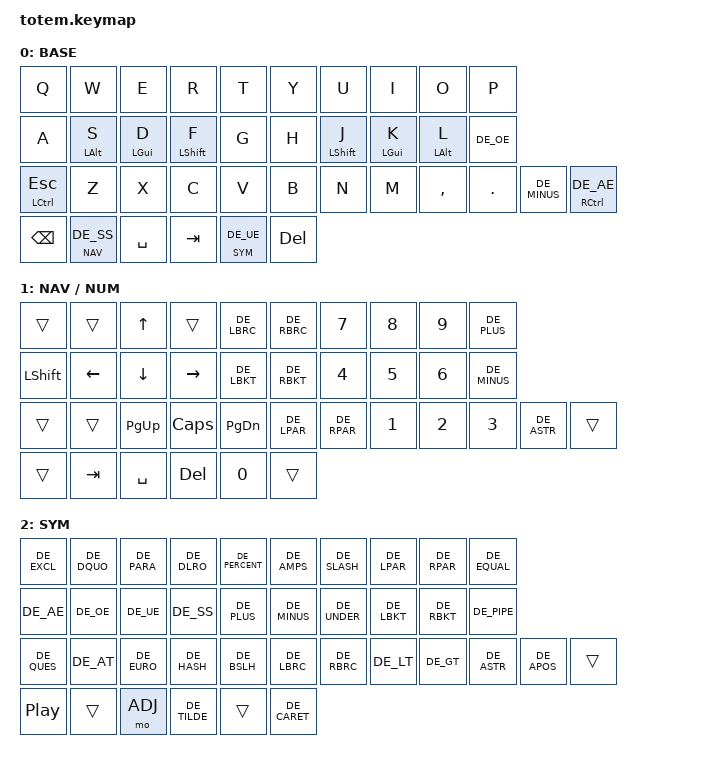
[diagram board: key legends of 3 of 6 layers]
/*
 * Totem ZMK Keymap - German macOS Optimization
 * Active working keymap for the Totem dongle setup.
 *
 * The visual layer diagrams are intentionally kept close to
 * `config/totem.keymap_original` so the layout stays easy to tune by hand.
 *
 *                                                       ▀▀▀▀▀     ▀▀▀▀▀          ▀▀█▀▀
 *                                                       ▄▀▀▀▄  ▄  ▄▀▀▀▄  ▄  ▄▀▀▀▄  █  ▄▀▀▀▄
 *                                                       █   █  █  █   █  █  █   █  █  █   █
 *                                                        ▀▀▀   █   ▀▀▀   █   ▀▀▀   ▀   ▀▀▀
 *                                                              █      ▄▄▄█▄▄▄    █   █
 *                                                              ▀      █  █  █     █▄█
 *                                                            ▀▀▀▀▀    █  █  █      ▀
 *                                                                     ▀  ▀  ▀
 */

#include <behaviors.dtsi>
#include <dt-bindings/zmk/bt.h>
#include <dt-bindings/zmk/keys.h>
#include <dt-bindings/zmk/outputs.h>

// ==================================================================================
// DEUTSCHE SONDERZEICHEN DEFINITIONEN (GERMAN CHARACTER MAPPINGS)
// ==================================================================================

// UMLAUTE & ESS-ZETT (Umlauts & Sharp S)
#define DE_UE      LBKT          // Ü
#define DE_OE      SEMI          // Ö
#define DE_AE      SQT           // Ä
#define DE_SS      MINUS         // ß

// KLAMMERN (Brackets) - German macOS optimized for Layer 2
#define DE_LBRC    LA(N8)        // { (Option+8)
#define DE_RBRC    LA(N9)        // } (Option+9)
#define DE_LBKT    LA(N5)        // [ (Option+5)
#define DE_RBKT    LA(N6)        // ] (Option+6)
#define DE_LPAR    LS(N8)        // (
#define DE_RPAR    LS(N9)        // )

// MATHEMATISCHE ZEICHEN (Math & Operators)
#define DE_PLUS    RBKT          // +
#define DE_MINUS   FSLH          // -
#define DE_EQUAL   LS(N0)        // =
#define DE_ASTR    LS(RBKT)      // *
#define DE_SLASH   LS(N7)        // /
#define DE_BSLH    LA(LS(N7))    // \ (Option+Shift+7)
#define DE_PERCENT LS(N5)        // %

// SONDERZEICHEN (Special Characters)
#define DE_EXCL    LS(N1)        // !
#define DE_DQUO    LS(N2)        // "
#define DE_PARA    LS(N3)        // §
#define DE_DLRO    LS(N4)        // $
#define DE_AMPS    LS(N6)        // &
#define DE_APOS    LS(NUHS)      // '
#define DE_CARET   NUBS          // ^ (German macOS / Totem)
#define DE_TILDE   LA(N)         // ~ (dead key on macOS)
#define DE_AT      LA(L)         // @ (Option+L)
#define DE_EURO    LA(E)         // € (Option+E)
#define DE_PIPE    LA(N7)        // | (Option+7)
#define DE_HASH    NUHS          // #
#define DE_QUES    LS(MINUS)     // ?
#define DE_LT      GRAVE         // <
#define DE_GT      LS(GRAVE)     // >
#define DE_UNDER   LS(MINUS)     // _

// -----------------------------------------------------------------------------------------

#define BASE 0
#define NAV  1
#define SYM  2
#define ADJ  3
#define TVP1 4
#define TVP2 5

&mt {
    quick-tap-ms = <150>;
    global-quick-tap;
    flavor = "tap-preferred";
    tapping-term-ms = <170>;
};

/ {
    combos {
        compatible = "zmk,combos";

        dash {
            bindings = <&kp DE_MINUS>; 
            key-positions = <19 31>;
            timeout-ms = <70>;
        };

        tilde_combo {
            bindings = <&kp DE_TILDE>;
            key-positions = <0 20>;
            timeout-ms = <60>;
        };

        enter_combo {
            bindings = <&kp ENTER>;
            key-positions = <13 12 11>;
            timeout-ms = <70>;
        };

        enter_right_combo {
            bindings = <&kp ENTER>;
            key-positions = <16 18 17>;
            timeout-ms = <70>;
        };
    };

    behaviors {
        mt_left: mt_left {
            compatible = "zmk,behavior-hold-tap";
            label = "MT_LEFT";
            bindings = <&kp>, <&kp>;

            #binding-cells = <2>;
            tapping-term-ms = <400>;
            quick-tap-ms = <170>;
            flavor = "balanced";
            hold-trigger-key-positions = <26 27 16 15 5 6 7 5 6 7 8 9 15 16 17 18 19 26 27 28 29 31 5 6 7 8 9 15 16 17 18 19 26 27 28 29 30 31 35 36 37 32 33 34>;
            require-prior-idle-ms = <50>;
            hold-trigger-on-release;
        };

        mt_right: mt_right {
            compatible = "zmk,behavior-hold-tap";
            label = "MT_RIGHT";
            bindings = <&kp>, <&kp>;

            #binding-cells = <2>;
            tapping-term-ms = <400>;
            quick-tap-ms = <170>;
            flavor = "balanced";
            require-prior-idle-ms = <50>;
            hold-trigger-on-release;
            hold-trigger-key-positions = <0 1 4 10 11 12 13 14 20 21 22 23 24 25 2 35 36 37 3 32 33 34>;
        };

        mt_thumb: mt_thumb {
            compatible = "zmk,behavior-hold-tap";
            label = "MT_THUMB";
            bindings = <&kp>, <&kp>;

            #binding-cells = <2>;
            quick-tap-ms = <220>;
            flavor = "balanced";
            tapping-term-ms = <200>;
            require-prior-idle-ms = <0>;
        };

        mt_shift_left: mt_shift_left {
            compatible = "zmk,behavior-hold-tap";
            label = "MT_SHIFT_LEFT";
            bindings = <&kp>, <&kp>;

            #binding-cells = <2>;
            tapping-term-ms = <175>;
            quick-tap-ms = <175>;
            flavor = "tap-preferred";
            hold-trigger-key-positions = <19 26 27 29 30 31 36 37 35 36 32 33 34 5 6 7 8 9 15 16 17 18 19 26 27 28 29 31>;
            require-prior-idle-ms = <20>;
        };

        mt_shift_right: mt_shift_right {
            compatible = "zmk,behavior-hold-tap";
            label = "MT_SHIFT_RIGHT";
            bindings = <&kp>, <&kp>;

            #binding-cells = <2>;
            tapping-term-ms = <175>;
            quick-tap-ms = <175>;
            flavor = "tap-preferred";
            hold-trigger-key-positions = <0 1 2 3 4 10 11 12 13 14 20 21 22 23 24 25 32 33 34 35 36 37>;
            require-prior-idle-ms = <20>;
        };

        hold_sticky: hold_sticky {
            compatible = "zmk,behavior-hold-tap";
            label = "HOLD_STICKY";
            bindings = <&kp>, <&sk>;

            #binding-cells = <2>;
            flavor = "hold-preferred";
            tapping-term-ms = <150>;
            quick-tap-ms = <220>;
        };

        mt_all: mt_all {
            compatible = "zmk,behavior-hold-tap";
            label = "MT_ALL";
            bindings = <&kp>, <&kp>;

            #binding-cells = <2>;
            tapping-term-ms = <175>;
            quick-tap-ms = <175>;
            flavor = "balanced";
            require-prior-idle-ms = <35>;
            hold-trigger-on-release;
        };
    };

    keymap {
        compatible = "zmk,keymap";

        // ▄▄▄▄▄▄▄▄▄▄▄▄▄▄▄▄▄▄▄▄▄▄▄▄▄▄▄▄▄▄▄▄▄▄▄▄▄▄▄▄▄▄▄▄▄▄▄▄▄▄▄▄▄▄▄▄▄▄▄▄▄▄▄▄▄▄▄▄▄▄▄▄▄▄▄▄▄▄▄▄▄▄▄▄▄▄▄▄▄▄▄▄▄▄▄▄▄▄▄▄▄▄▄▄▄▄▄▄▄▄▄▄▄▄▄▄▄▄▄▄▄▄▄▄▄▄▄▄▄▄▄▄▄▄▄▄▄▄▄▄▄▄▄▄▄▄▄▄▄

        base_layer {
            // ┏━━━━━━━━━━━━━━━━━━━━━━━━━━━━━━━━━━━━━━━┓

            label = "BASE";

            // ┗━━━━━━━━━━━━━━━━━━━━━━━━━━━━━━━━━━━━━━━┛
            //             ┏━━━━━━━━━━━┳━━━━━━━━━━━┳━━━━━━━━━━━┳━━━━━━━━━━━┳━━━━━━━━━━━┓   ┏━━━━━━━━━━━┳━━━━━━━━━━━┳━━━━━━━━━━━┳━━━━━━━━━━━┳━━━━━━━━━━━┓
            //             ┃     Q     ┃     W     ┃     E     ┃     R     ┃     T     ┃   ┃     Y     ┃     U     ┃     I     ┃     O     ┃     P     ┃
            //             ┣━━━━━━━━━━━╋━━━━━━━━━━━╋━━━━━━━━━━━╋━━━━━━━━━━━╋━━━━━━━━━━━┫   ┣━━━━━━━━━━━╋━━━━━━━━━━━╋━━━━━━━━━━━╋━━━━━━━━━━━╋━━━━━━━━━━━┫
            //             ┃     A     ┃     S     ┃     D     ┃     F     ┃     G     ┃   ┃     H     ┃     J     ┃     K     ┃     L     ┃     Ö     ┃
            // ┏━━━━━━━━━━━╋━━━━━━━━━━━╋━━━━━━━━━━━╋━━━━━━━━━━━╋━━━━━━━━━━━╋━━━━━━━━━━━┫   ┣━━━━━━━━━━━╋━━━━━━━━━━━╋━━━━━━━━━━━╋━━━━━━━━━━━╋━━━━━━━━━━━╋━━━━━━━━━━━┓
            // ┃ ESC / Ctrl┃     Z     ┃     X     ┃     C     ┃     V     ┃     B     ┃   ┃     N     ┃     M     ┃     ,     ┃     .     ┃     -     ┃ Ä / Ctrl  ┃
            // ┗━━━━━━━━━━━┻━━━━━━━━━━━┻━━━━━━━━━━━╋━━━━━━━━━━━╋━━━━━━━━━━━╋━━━━━━━━━━━┫   ┣━━━━━━━━━━━╋━━━━━━━━━━━╋━━━━━━━━━━━╋━━━━━━━━━━━┻━━━━━━━━━━━┻━━━━━━━━━━━┛
            //                                     ┃   BSPC    ┃   ß/NAV   ┃    SPC    ┃   ┃    TAB    ┃   Ü/SYM   ┃    DEL    ┃
            //                                     ┗━━━━━━━━━━━┻━━━━━━━━━━━┻━━━━━━━━━━━┛   ┗━━━━━━━━━━━┻━━━━━━━━━━━┻━━━━━━━━━━━┛

            bindings = <
                &kp Q  &kp W  &kp E  &kp R  &kp T         &kp Y  &kp U  &kp I  &kp O  &kp P
                &kp A  &mt_shift_left LALT S  &mt_left LGUI D  &mt_shift_left LSHIFT F  &kp G         &kp H  &mt_shift_right LSHIFT J  &mt_right LGUI K  &mt_shift_right LALT L  &kp DE_OE
                &mt_all LEFT_CONTROL ESCAPE  &kp Z  &kp X  &kp C  &kp V  &kp B         &kp N  &kp M  &kp COMMA  &kp DOT  &kp DE_MINUS  &mt_all RCTRL DE_AE
                &kp BACKSPACE  &lt NAV DE_SS  &kp SPACE    &kp TAB  &lt SYM DE_UE  &kp DELETE
            >;
        };

        // ▄▄▄▄▄▄▄▄▄▄▄▄▄▄▄▄▄▄▄▄▄▄▄▄▄▄▄▄▄▄▄▄▄▄▄▄▄▄▄▄▄▄▄▄▄▄▄▄▄▄▄▄▄▄▄▄▄▄▄▄▄▄▄▄▄▄▄▄▄▄▄▄▄▄▄▄▄▄▄▄▄▄▄▄▄▄▄▄▄▄▄▄▄▄▄▄▄▄▄▄▄▄▄▄▄▄▄▄▄▄▄▄▄▄▄▄▄▄▄▄▄▄▄▄▄▄▄▄▄▄▄▄▄▄▄▄▄▄▄▄▄▄▄▄▄▄▄▄▄

        nav_layer {
            // ┏━━━━━━━━━━━━━━━━━━━━━━━━━━━━━━━━━━━━━━━┓

            label = "NAV / NUM";

            // ┗━━━━━━━━━━━━━━━━━━━━━━━━━━━━━━━━━━━━━━━┛
            //             ┏━━━━━━━━━━━┳━━━━━━━━━━━┳━━━━━━━━━━━┳━━━━━━━━━━━┳━━━━━━━━━━━┓   ┏━━━━━━━━━━━┳━━━━━━━━━━━┳━━━━━━━━━━━┳━━━━━━━━━━━┳━━━━━━━━━━━┓
            //             ┃           ┃           ┃     UP    ┃           ┃     {     ┃   ┃     }     ┃     7     ┃     8     ┃     9     ┃     +     ┃
            //             ┣━━━━━━━━━━━╋━━━━━━━━━━━╋━━━━━━━━━━━╋━━━━━━━━━━━╋━━━━━━━━━━━┫   ┣━━━━━━━━━━━╋━━━━━━━━━━━╋━━━━━━━━━━━╋━━━━━━━━━━━╋━━━━━━━━━━━┫
            //             ┃   SHIFT   ┃   LEFT    ┃    DOWN   ┃   RIGHT   ┃     [     ┃   ┃     ]     ┃     4     ┃     5     ┃     6     ┃     -     ┃
            // ┏━━━━━━━━━━━╋━━━━━━━━━━━╋━━━━━━━━━━━╋━━━━━━━━━━━╋━━━━━━━━━━━╋━━━━━━━━━━━┫   ┣━━━━━━━━━━━╋━━━━━━━━━━━╋━━━━━━━━━━━╋━━━━━━━━━━━╋━━━━━━━━━━━╋━━━━━━━━━━━┓
            // ┃           ┃           ┃   P UP    ┃  C LOCK   ┃  P DOWN   ┃     (     ┃   ┃     )     ┃     1     ┃     2     ┃     3     ┃     *     ┃           ┃
            // ┗━━━━━━━━━━━┻━━━━━━━━━━━┻━━━━━━━━━━━╋━━━━━━━━━━━╋━━━━━━━━━━━╋━━━━━━━━━━━┫   ┣━━━━━━━━━━━╋━━━━━━━━━━━╋━━━━━━━━━━━╋━━━━━━━━━━━┻━━━━━━━━━━━┻━━━━━━━━━━━┛
            //                                     ┃           ┃    TAB    ┃    SPC    ┃   ┃    DEL    ┃     0     ┃           ┃
            //                                     ┗━━━━━━━━━━━┻━━━━━━━━━━━┻━━━━━━━━━━━┛   ┗━━━━━━━━━━━┻━━━━━━━━━━━┻━━━━━━━━━━━┛

            bindings = <
                &trans      &trans      &kp UP        &trans         &kp DE_LBRC    &kp DE_RBRC  &kp N7  &kp N8  &kp N9  &kp DE_PLUS
                &kp LSHFT   &kp LEFT    &kp DOWN      &kp RIGHT      &kp DE_LBKT    &kp DE_RBKT  &kp N4  &kp N5  &kp N6  &kp DE_MINUS
                &trans      &trans      &kp PG_UP     &kp CAPSLOCK   &kp PG_DN      &kp DE_LPAR  &kp DE_RPAR  &kp N1  &kp N2  &kp N3  &kp DE_ASTR  &trans
                &trans      &kp TAB     &kp SPACE     &kp DELETE     &kp N0         &trans
            >;
        };

        // ▄▄▄▄▄▄▄▄▄▄▄▄▄▄▄▄▄▄▄▄▄▄▄▄▄▄▄▄▄▄▄▄▄▄▄▄▄▄▄▄▄▄▄▄▄▄▄▄▄▄▄▄▄▄▄▄▄▄▄▄▄▄▄▄▄▄▄▄▄▄▄▄▄▄▄▄▄▄▄▄▄▄▄▄▄▄▄▄▄▄▄▄▄▄▄▄▄▄▄▄▄▄▄▄▄▄▄▄▄▄▄▄▄▄▄▄▄▄▄▄▄▄▄▄▄▄▄▄▄▄▄▄▄▄▄▄▄▄▄▄▄▄▄▄▄▄▄▄▄

        sim_layer {
            // ┏━━━━━━━━━━━━━━━━━━━━━━━━━━━━━━━━━━━━━━━┓

            label = "SYM";

            // ┗━━━━━━━━━━━━━━━━━━━━━━━━━━━━━━━━━━━━━━━┛
            //             ┏━━━━━━━━━━━┳━━━━━━━━━━━┳━━━━━━━━━━━┳━━━━━━━━━━━┳━━━━━━━━━━━┓   ┏━━━━━━━━━━━┳━━━━━━━━━━━┳━━━━━━━━━━━┳━━━━━━━━━━━┳━━━━━━━━━━━┓
            //             ┃     !     ┃     "     ┃     §     ┃     $     ┃     %     ┃   ┃     &     ┃     /     ┃     (     ┃     )     ┃     =     ┃
            //             ┣━━━━━━━━━━━╋━━━━━━━━━━━╋━━━━━━━━━━━╋━━━━━━━━━━━╋━━━━━━━━━━━┫   ┣━━━━━━━━━━━╋━━━━━━━━━━━╋━━━━━━━━━━━╋━━━━━━━━━━━╋━━━━━━━━━━━┫
            //             ┃     Ä     ┃     Ö     ┃     Ü     ┃     ß     ┃     +     ┃   ┃     -     ┃     _     ┃     [     ┃     ]     ┃     |     ┃
            // ┏━━━━━━━━━━━╋━━━━━━━━━━━╋━━━━━━━━━━━╋━━━━━━━━━━━╋━━━━━━━━━━━╋━━━━━━━━━━━┫   ┣━━━━━━━━━━━╋━━━━━━━━━━━╋━━━━━━━━━━━╋━━━━━━━━━━━╋━━━━━━━━━━━╋━━━━━━━━━━━┓
            // ┃     ?     ┃     @     ┃     €     ┃     #     ┃     \     ┃     {     ┃   ┃     }     ┃     <     ┃     >     ┃     *     ┃     '     ┃           ┃
            // ┗━━━━━━━━━━━┻━━━━━━━━━━━┻━━━━━━━━━━━╋━━━━━━━━━━━╋━━━━━━━━━━━╋━━━━━━━━━━━┫   ┣━━━━━━━━━━━╋━━━━━━━━━━━╋━━━━━━━━━━━╋━━━━━━━━━━━┻━━━━━━━━━━━┻━━━━━━━━━━━┛
            //                                     ┃  PLAY/PAUSE┃          ┃    ADJ    ┃   ┃     ~     ┃           ┃     ^     ┃
            //                                     ┗━━━━━━━━━━━┻━━━━━━━━━━━┻━━━━━━━━━━━┛   ┗━━━━━━━━━━━┻━━━━━━━━━━━┻━━━━━━━━━━━┛

            bindings = <
                &kp DE_EXCL  &kp DE_DQUO  &kp DE_PARA  &kp DE_DLRO  &kp DE_PERCENT    &kp DE_AMPS  &kp DE_SLASH  &kp DE_LPAR  &kp DE_RPAR  &kp DE_EQUAL
                &kp DE_AE    &kp DE_OE    &kp DE_UE    &kp DE_SS    &kp DE_PLUS       &kp DE_MINUS &kp DE_UNDER  &kp DE_LBKT  &kp DE_RBKT  &kp DE_PIPE
                &kp DE_QUES  &kp DE_AT    &kp DE_EURO  &kp DE_HASH  &kp DE_BSLH       &kp DE_LBRC  &kp DE_RBRC   &kp DE_LT    &kp DE_GT    &kp DE_ASTR  &kp DE_APOS  &trans
                &kp C_PP     &trans       &mo ADJ      &kp DE_TILDE &trans            &kp DE_CARET
            >;
        };

        // ▄▄▄▄▄▄▄▄▄▄▄▄▄▄▄▄▄▄▄▄▄▄▄▄▄▄▄▄▄▄▄▄▄▄▄▄▄▄▄▄▄▄▄▄▄▄▄▄▄▄▄▄▄▄▄▄▄▄▄▄▄▄▄▄▄▄▄▄▄▄▄▄▄▄▄▄▄▄▄▄▄▄▄▄▄▄▄▄▄▄▄▄▄▄▄▄▄▄▄▄▄▄▄▄▄▄▄▄▄▄▄▄▄▄▄▄▄▄▄▄▄▄▄▄▄▄▄▄▄▄▄▄▄▄▄▄▄▄▄▄▄▄▄▄▄▄▄▄▄

        adjust_layer {
            // ┏━━━━━━━━━━━━━━━━━━━━━━━━━━━━━━━━━━━━━━━┓

            label = "ADJ";

            // ┗━━━━━━━━━━━━━━━━━━━━━━━━━━━━━━━━━━━━━━━┛
            //             ┏━━━━━━━━━━━┳━━━━━━━━━━━┳━━━━━━━━━━━┳━━━━━━━━━━━┳━━━━━━━━━━━┓   ┏━━━━━━━━━━━┳━━━━━━━━━━━┳━━━━━━━━━━━┳━━━━━━━━━━━┳━━━━━━━━━━━┓
            //             ┃   RESET   ┃ BT CLEAR  ┃  OUT TOG  ┃           ┃           ┃   ┃           ┃    F7     ┃    F8     ┃    F9     ┃    F12    ┃
            //             ┣━━━━━━━━━━━╋━━━━━━━━━━━╋━━━━━━━━━━━╋━━━━━━━━━━━╋━━━━━━━━━━━┫   ┣━━━━━━━━━━━╋━━━━━━━━━━━╋━━━━━━━━━━━╋━━━━━━━━━━━╋━━━━━━━━━━━┫
            //             ┃ BOOTLOAD  ┃ BT NEXT   ┃           ┃           ┃           ┃   ┃           ┃    F4     ┃    F5     ┃    F6     ┃    F11    ┃
            // ┏━━━━━━━━━━━╋━━━━━━━━━━━╋━━━━━━━━━━━╋━━━━━━━━━━━╋━━━━━━━━━━━╋━━━━━━━━━━━┫   ┣━━━━━━━━━━━╋━━━━━━━━━━━╋━━━━━━━━━━━╋━━━━━━━━━━━╋━━━━━━━━━━━╋━━━━━━━━━━━┓
            // ┃           ┃ BT PREV   ┃           ┃           ┃           ┃           ┃   ┃    F1     ┃    F2     ┃    F3     ┃    F10    ┃           ┃           ┃
            // ┗━━━━━━━━━━━┻━━━━━━━━━━━┻━━━━━━━━━━━╋━━━━━━━━━━━╋━━━━━━━━━━━╋━━━━━━━━━━━┫   ┣━━━━━━━━━━━╋━━━━━━━━━━━╋━━━━━━━━━━━╋━━━━━━━━━━━┻━━━━━━━━━━━┻━━━━━━━━━━━┛
            //                                     ┃           ┃           ┃           ┃   ┃           ┃           ┃           ┃
            //                                     ┗━━━━━━━━━━━┻━━━━━━━━━━━┻━━━━━━━━━━━┛   ┗━━━━━━━━━━━┻━━━━━━━━━━━┻━━━━━━━━━━━┛

            bindings = <
                &sys_reset  &bt BT_CLR  &out OUT_TOG  &trans  &trans    &trans  &kp F7  &kp F8  &kp F9  &kp F12
                &bootloader  &bt BT_NXT  &trans  &trans  &trans    &trans  &kp F4  &kp F5  &kp F6  &kp F11
                &trans  &bt BT_PRV  &trans  &trans  &trans    &kp F1  &kp F2  &kp F3  &kp F10  &trans
                &trans  &trans  &trans    &trans  &trans  &trans
            >;
        };

        // ▄▄▄▄▄▄▄▄▄▄▄▄▄▄▄▄▄▄▄▄▄▄▄▄▄▄▄▄▄▄▄▄▄▄▄▄▄▄▄▄▄▄▄▄▄▄▄▄▄▄▄▄▄▄▄▄▄▄▄▄▄▄▄▄▄▄▄▄▄▄▄▄▄▄▄▄▄▄▄▄▄▄▄▄▄▄▄▄▄▄▄▄▄▄▄▄▄▄▄▄▄▄▄▄▄▄▄▄▄▄▄▄▄▄▄▄▄▄▄▄▄▄▄▄▄▄▄▄▄▄▄▄▄▄▄▄▄▄▄▄▄▄▄▄▄▄▄▄▄

        tvp1_layer {
            // ┏━━━━━━━━━━━━━━━━━━━━━━━━━━━━━━━━━━━━━━━┓

            label = "TVP 1";

            // ┗━━━━━━━━━━━━━━━━━━━━━━━━━━━━━━━━━━━━━━━┛
            //             ┏━━━━━━━━━━━┳━━━━━━━━━━━┳━━━━━━━━━━━┳━━━━━━━━━━━┳━━━━━━━━━━━┓   ┏━━━━━━━━━━━┳━━━━━━━━━━━┳━━━━━━━━━━━┳━━━━━━━━━━━┳━━━━━━━━━━━┓
            //             ┃ NEXT FILE ┃ MARK IN   ┃ ROTATE    ┃ MARK OUT  ┃ SHOW SNAP ┃   ┃           ┃           ┃           ┃           ┃           ┃
            //             ┣━━━━━━━━━━━╋━━━━━━━━━━━╋━━━━━━━━━━━╋━━━━━━━━━━━╋━━━━━━━━━━━┫   ┣━━━━━━━━━━━╋━━━━━━━━━━━╋━━━━━━━━━━━╋━━━━━━━━━━━╋━━━━━━━━━━━┫
            //             ┃  TVP II   ┃   LEFT    ┃    ALT    ┃   RIGHT   ┃   SPACE   ┃   ┃           ┃           ┃           ┃           ┃           ┃
            // ┏━━━━━━━━━━━╋━━━━━━━━━━━╋━━━━━━━━━━━╋━━━━━━━━━━━╋━━━━━━━━━━━╋━━━━━━━━━━━┫   ┣━━━━━━━━━━━╋━━━━━━━━━━━╋━━━━━━━━━━━╋━━━━━━━━━━━╋━━━━━━━━━━━╋━━━━━━━━━━━┓
            // ┃     J     ┃   SHIFT   ┃   COPY    ┃   BSPC    ┃   PASTE   ┃ IMG MARK  ┃   ┃           ┃           ┃           ┃           ┃           ┃           ┃
            // ┗━━━━━━━━━━━┻━━━━━━━━━━━┻━━━━━━━━━━━╋━━━━━━━━━━━╋━━━━━━━━━━━╋━━━━━━━━━━━┫   ┣━━━━━━━━━━━╋━━━━━━━━━━━╋━━━━━━━━━━━╋━━━━━━━━━━━┻━━━━━━━━━━━┻━━━━━━━━━━━┛
            //                                     ┃           ┃ UNDO/SAVE ┃  SEL/MOV  ┃   ┃           ┃           ┃           ┃
            //                                     ┗━━━━━━━━━━━┻━━━━━━━━━━━┻━━━━━━━━━━━┛   ┗━━━━━━━━━━━┻━━━━━━━━━━━┻━━━━━━━━━━━┛

            bindings = <
                &kp TAB  &kp I  &kp LC(LALT)  &kp O  &kp LC(F20)    &trans  &none  &none  &none  &none
                &lt TVP2 L  &kp LEFT  &kp LALT  &kp RIGHT  &kp SPACE      &trans  &none  &none  &none  &none
                &kp J  &kp LSHFT  &kp LC(C)  &kp BSPC  &kp LC(V)  &kp LC(F19)  &trans  &trans  &trans  &trans
                &trans  &kp LC(F14)  &kp LC(F13)    &trans  &trans  &trans
            >;
        };

        // ▄▄▄▄▄▄▄▄▄▄▄▄▄▄▄▄▄▄▄▄▄▄▄▄▄▄▄▄▄▄▄▄▄▄▄▄▄▄▄▄▄▄▄▄▄▄▄▄▄▄▄▄▄▄▄▄▄▄▄▄▄▄▄▄▄▄▄▄▄▄▄▄▄▄▄▄▄▄▄▄▄▄▄▄▄▄▄▄▄▄▄▄▄▄▄▄▄▄▄▄▄▄▄▄▄▄▄▄▄▄▄▄▄▄▄▄▄▄▄▄▄▄▄▄▄▄▄▄▄▄▄▄▄▄▄▄▄▄▄▄▄▄▄▄▄▄▄▄▄

        tvp2_layer {
            // ┏━━━━━━━━━━━━━━━━━━━━━━━━━━━━━━━━━━━━━━━┓

            label = "TVP 2";

            // ┗━━━━━━━━━━━━━━━━━━━━━━━━━━━━━━━━━━━━━━━┛
            //             ┏━━━━━━━━━━━┳━━━━━━━━━━━┳━━━━━━━━━━━┳━━━━━━━━━━━┳━━━━━━━━━━━┓   ┏━━━━━━━━━━━┳━━━━━━━━━━━┳━━━━━━━━━━━┳━━━━━━━━━━━┳━━━━━━━━━━━┓
            //             ┃ SOLO      ┃ TOGGLE IN ┃ RESET ROT ┃ TOGGLE OUT┃ TAKE SNAP ┃   ┃           ┃    F7     ┃    F8     ┃    F9     ┃    F12    ┃
            //             ┣━━━━━━━━━━━╋━━━━━━━━━━━╋━━━━━━━━━━━╋━━━━━━━━━━━╋━━━━━━━━━━━┫   ┣━━━━━━━━━━━╋━━━━━━━━━━━╋━━━━━━━━━━━╋━━━━━━━━━━━╋━━━━━━━━━━━┫
            //             ┃           ┃ LAST KEY  ┃ NEW KEY   ┃ NEXT KEY  ┃   ENTER   ┃   ┃           ┃    F4     ┃    F5     ┃    F6     ┃    F11    ┃
            // ┏━━━━━━━━━━━╋━━━━━━━━━━━╋━━━━━━━━━━━╋━━━━━━━━━━━╋━━━━━━━━━━━╋━━━━━━━━━━━┫   ┣━━━━━━━━━━━╋━━━━━━━━━━━╋━━━━━━━━━━━╋━━━━━━━━━━━╋━━━━━━━━━━━╋━━━━━━━━━━━┓
            // ┃           ┃     J     ┃ CPY2BRUSH ┃ DEL HEAD  ┃ PSTinPLACE┃ BOOK MARK ┃   ┃           ┃           ┃           ┃           ┃           ┃           ┃
            // ┗━━━━━━━━━━━┻━━━━━━━━━━━┻━━━━━━━━━━━╋━━━━━━━━━━━╋━━━━━━━━━━━╋━━━━━━━━━━━┫   ┣━━━━━━━━━━━╋━━━━━━━━━━━╋━━━━━━━━━━━╋━━━━━━━━━━━┻━━━━━━━━━━━┻━━━━━━━━━━━┛
            //                                     ┃           ┃ REDO/SAV1 ┃TRANS/WARP ┃   ┃           ┃           ┃           ┃
            //                                     ┗━━━━━━━━━━━┻━━━━━━━━━━━┻━━━━━━━━━━━┛   ┗━━━━━━━━━━━┻━━━━━━━━━━━┻━━━━━━━━━━━┛

            bindings = <
                &kp LC(F18)  &kp LS(I)  &kp LS(HOME)  &kp LS(O)  &kp LS(F)       &trans  &kp F7  &kp F8  &kp F9  &kp F12
                &trans  &kp LS(LEFT)  &kp LC(F17)  &kp LS(RIGHT)  &kp RET         &trans  &kp F4  &kp F5  &kp F6  &kp F11
                &trans  &kp J  &kp LS(C)  &kp LC(F16)  &kp LS(V)  &kp LC(F15)  &trans  &trans  &trans  &trans
                &trans  &kp LC(F12)  &kp LC(F11)     &trans  &trans  &trans
            >;
        };
    };
};
